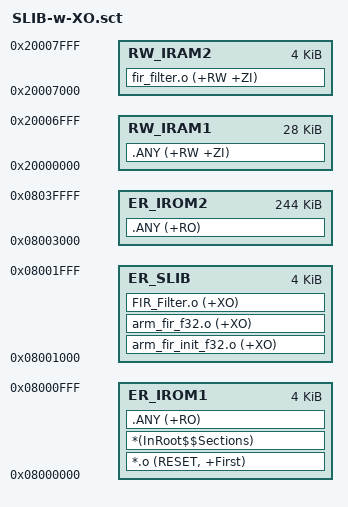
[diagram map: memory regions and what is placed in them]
; *************************************************************
; *** Scatter-Loading Description File generated by uVision ***
; *************************************************************

; This Scatter file is used for AT32F413RCT7 ( flash size is 256KB, page size is 2KB)

LR_IROM1 0x08000000 0x00001000  {    ; load region size_region
  ER_IROM1 0x08000000 0x00001000  {  ; load address = execution address
   *.o (RESET, +First)
   *(InRoot$$Sections)
   .ANY (+RO)
  }
  RW_IRAM1 0x20000000 0x00007000  {  ; RW data
   .ANY (+RW +ZI)
  }
  
  RW_IRAM2 0x20007000 0x00001000  {  ; RW data
   fir_filter.o (+RW +ZI) 
  }  
  
}

LR_SLIB 0x08001000 0x00001000  {
  ER_SLIB 0x08001000 0x00001000  {  ; load address = execution address
    
	arm_fir_init_f32.o (+XO)
	arm_fir_f32.o (+XO)
	FIR_Filter.o (+XO)
  }
}

;0x08002000 ~ 0x08002FFF is SLIB Data area

LR_IROM2 0x08003000 0x0003D000  {    ; load region size_region
  ER_IROM2 0x08003000 0x0003D000  {  ; load address = execution address
   .ANY (+RO)
  }
}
